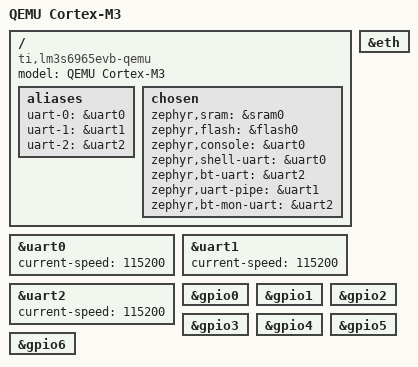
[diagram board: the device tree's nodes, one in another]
/* SPDX-License-Identifier: Apache-2.0 */

/dts-v1/;

#include <ti/lm3s6965.dtsi>

/ {
	model = "QEMU Cortex-M3";
	compatible = "ti,lm3s6965evb-qemu", "ti,lm3s6965";

	aliases {
		uart-0 = &uart0;
		uart-1 = &uart1;
		uart-2 = &uart2;
	};

	chosen {
		zephyr,sram = &sram0;
		zephyr,flash = &flash0;
		zephyr,console = &uart0;
		zephyr,shell-uart = &uart0;
		zephyr,bt-uart = &uart2;
		zephyr,uart-pipe = &uart1;
		zephyr,bt-mon-uart = &uart2;
	};
};

&uart0 {
	status = "okay";
	current-speed = <115200>;
};

&uart1 {
	status = "okay";
	current-speed = <115200>;
};

&uart2 {
	status = "okay";
	current-speed = <115200>;
};

&eth {
	status = "okay";
};

&gpio0 {
       status = "okay";
};

&gpio1 {
       status = "okay";
};

&gpio2 {
       status = "okay";
};

&gpio3 {
       status = "okay";
};

&gpio4 {
       status = "okay";
};

&gpio5 {
       status = "okay";
};

&gpio6 {
       status = "okay";
};
